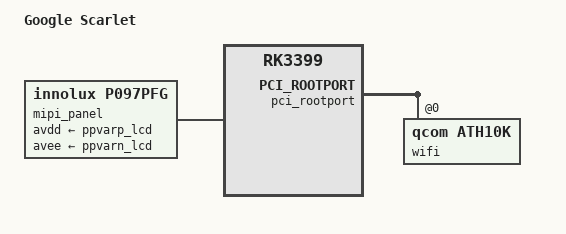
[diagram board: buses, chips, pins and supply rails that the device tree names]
// SPDX-License-Identifier: (GPL-2.0+ OR MIT)
/*
 * Google Gru-Scarlet Rev5+ (SKU-0) board device tree source
 *
 * Copyright 2021 Google LLC.
 */

/dts-v1/;

#include "rk3399-gru-scarlet.dtsi"

/ {
	model = "Google Scarlet";
	compatible = "google,scarlet-rev15-sku0", "google,scarlet-rev15",
		     "google,scarlet-rev14-sku0", "google,scarlet-rev14",
		     "google,scarlet-rev13-sku0", "google,scarlet-rev13",
		     "google,scarlet-rev12-sku0", "google,scarlet-rev12",
		     "google,scarlet-rev11-sku0", "google,scarlet-rev11",
		     "google,scarlet-rev10-sku0", "google,scarlet-rev10",
		     "google,scarlet-rev9-sku0",  "google,scarlet-rev9",
		     "google,scarlet-rev8-sku0",  "google,scarlet-rev8",
		     "google,scarlet-rev7-sku0",  "google,scarlet-rev7",
		     "google,scarlet-rev6-sku0",  "google,scarlet-rev6",
		     "google,scarlet-rev5-sku0",  "google,scarlet-rev5",
		     "google,scarlet", "google,gru", "rockchip,rk3399";
};

&mipi_panel {
	compatible = "innolux,p097pfg";
	avdd-supply = <&ppvarp_lcd>;
	avee-supply = <&ppvarn_lcd>;
};

&pci_rootport {
	wifi@0,0 {
		compatible = "qcom,ath10k";
		reg = <0x00000000 0x0 0x00000000 0x0 0x00000000>,
		      <0x03000010 0x0 0x00000000 0x0 0x00200000>;
		qcom,calibration-variant = "GO_DUMO";
	};
};
